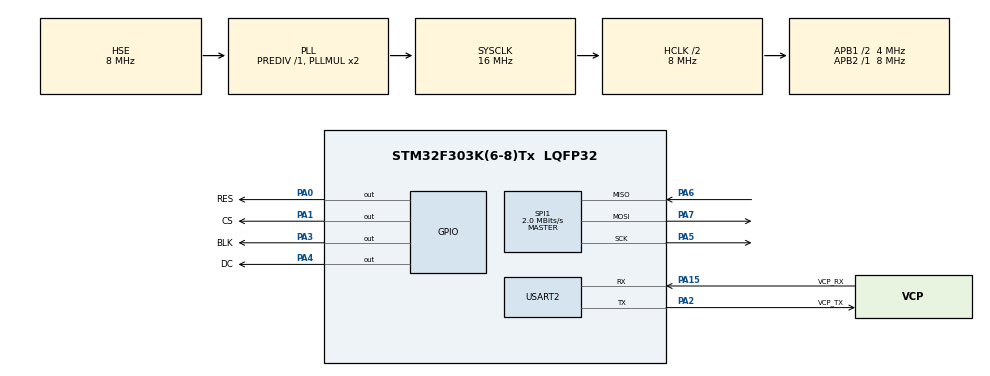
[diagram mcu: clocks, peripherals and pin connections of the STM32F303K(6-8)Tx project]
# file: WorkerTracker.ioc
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Mcu.Family=STM32F3
Mcu.Name=STM32F303K(6-8)Tx
Mcu.Package=LQFP32
NVIC.PriorityGroup=NVIC_PRIORITYGROUP_4
PA0.GPIO_Label=RES
PA0.GPIO_PuPd=GPIO_PULLDOWN
PA0.Signal=GPIO_Output
PA1.GPIO_Label=CS
PA1.GPIO_PuPd=GPIO_PULLDOWN
PA1.PinState=GPIO_PIN_RESET
PA1.Signal=GPIO_Output
PA13.GPIO_Label=SWDIO
PA13.Mode=Serial_Wire
PA13.Signal=SYS_JTMS-SWDIO
PA14.GPIO_Label=SWCLK
PA14.Mode=Serial_Wire
PA14.Signal=SYS_JTCK-SWCLK
PA15.GPIO_Label=VCP_RX
PA15.Mode=Asynchronous
PA15.Signal=USART2_RX
PA2.GPIO_Label=VCP_TX
PA2.Mode=Asynchronous
PA2.Signal=USART2_TX
PA3.GPIO_Label=BLK
PA3.GPIO_PuPd=GPIO_PULLDOWN
PA3.Signal=GPIO_Output
PA4.GPIO_Label=DC
PA4.GPIO_PuPd=GPIO_PULLDOWN
PA4.Signal=GPIO_Output
PA5.Mode=Full_Duplex_Master
PA5.Signal=SPI1_SCK
PA6.Mode=Full_Duplex_Master
PA6.Signal=SPI1_MISO
PA7.Mode=Full_Duplex_Master
PA7.Signal=SPI1_MOSI
PF0\ /\ OSC_IN.GPIO_Label=MCO
PF0\ /\ OSC_IN.Mode=HSE-External-Clock-Source
PF0\ /\ OSC_IN.Signal=RCC_OSC_IN
ProjectManager.HeapSize=0x200
ProjectManager.StackSize=0x400
ProjectManager.TargetToolchain=STM32CubeIDE
RCC.AHBCLKDivider=RCC_SYSCLK_DIV2
RCC.AHBFreq_Value=8000000
RCC.APB1CLKDivider=RCC_HCLK_DIV2
RCC.APB1Freq_Value=4000000
RCC.APB1TimFreq_Value=8000000
RCC.APB2Freq_Value=8000000
RCC.APB2TimFreq_Value=8000000
RCC.CortexFreq_Value=8000000
RCC.HCLKFreq_Value=8000000
RCC.HSE_VALUE=8000000
RCC.HSI_VALUE=8000000
RCC.PLLSourceVirtual=RCC_PLLSOURCE_HSE
RCC.SYSCLKFreq_VALUE=16000000
RCC.SYSCLKSourceVirtual=RCC_SYSCLKSOURCE_PLLCLK
SPI1.BaudRatePrescaler=SPI_BAUDRATEPRESCALER_4
SPI1.CalculateBaudRate=2.0 MBits/s
SPI1.DataSize=SPI_DATASIZE_8BIT
SPI1.Direction=SPI_DIRECTION_2LINES
SPI1.Mode=SPI_MODE_MASTER
SPI1.VirtualType=VM_MASTER
USART2.VirtualMode-Asynchronous=VM_ASYNC
board=NUCLEO-F303K8

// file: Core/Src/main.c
/* USER CODE BEGIN Header */
/**
  ******************************************************************************
  * @file           : main.c
  * @brief          : Main program body
  ******************************************************************************
  * @attention
  *
  * Copyright (c) 2023 STMicroelectronics.
  * All rights reserved.
  *
  * This software is licensed under terms that can be found in the LICENSE file
  * in the root directory of this software component.
  * If no LICENSE file comes with this software, it is provided AS-IS.
  *
  ******************************************************************************
  */
/* USER CODE END Header */
#include "main.h"
#include "spi.h"
#include "usart.h"
#include "gpio.h"

/* USER CODE BEGIN Includes */
#include "st7789.h"
/* USER CODE END Includes */

void SystemClock_Config(void);

int main(void)
{

  /* MCU Configuration--------------------------------------------------------*/

  /* Reset of all peripherals, Initializes the Flash interface and the Systick. */
  HAL_Init();

  /* Configure the system clock */
  SystemClock_Config();

  /* Initialize all configured peripherals */
  MX_GPIO_Init();
  MX_USART2_UART_Init();
  MX_SPI1_Init();
  /* USER CODE BEGIN 2 */
//  SPI1->CR1 |= (1<<6);
  /* USER CODE END 2 */

  /* Infinite loop */
  /* USER CODE BEGIN WHILE */

  ST7789_Init(128, 128);
  	  // Инициализация входа для кнопки
      // Тест вывода основных цветов
//      ST7789_FillScreen(BLACK);
//      ST7789_SetBL(0);
  HAL_GPIO_WritePin(GPIOA, GPIO_PIN_3, 0);
  while (1)
  {
//	  ST7789_Init(128, 128);
////	  	  // Инициализация входа для кнопки
////	      // Тест вывода основных цветов
//	      ST7789_FillScreen(BLACK);
//	      ST7789_SetBL(100);
//
//
//	      uint16_t color = RGB565(255, 0, 0);
//	      ST7789_FillScreen(color);
//	      HAL_Delay(500);
//
//	      color = RGB565(0, 255, 0);
//	      ST7789_FillScreen(color);
//	      HAL_Delay(500);
//
//	      color = RGB565(50, 55, 50);
//	      ST7789_FillScreen(color);
//	      HAL_Delay(500);
//
//	      color = RGB565(0, 0, 255);
//	      ST7789_FillScreen(color);
//	      HAL_Delay(500);
//
//	      color = RGB565(255, 255, 0);
//	      ST7789_FillScreen(color);
//	      HAL_Delay(500);
//
//	      color = RGB565(255, 0, 255);
//	      ST7789_FillScreen(color);
//	      HAL_Delay(500);
//
//	      color = RGB565(0, 255, 255);
//	      ST7789_FillScreen(color);
//	      HAL_Delay(500);
//
//	      color = RGB565(255, 255, 255);
//	      ST7789_FillScreen(color);
//	      HAL_Delay(500);
    /* USER CODE END WHILE */

  }
}

void SystemClock_Config(void)
{
  RCC_OscInitTypeDef RCC_OscInitStruct = {0};
  RCC_ClkInitTypeDef RCC_ClkInitStruct = {0};

  /** Initializes the RCC Oscillators according to the specified parameters
  * in the RCC_OscInitTypeDef structure.
  */
  RCC_OscInitStruct.OscillatorType = RCC_OSCILLATORTYPE_HSE;
  RCC_OscInitStruct.HSEState = RCC_HSE_BYPASS;
  RCC_OscInitStruct.HSEPredivValue = RCC_HSE_PREDIV_DIV1;
  RCC_OscInitStruct.HSIState = RCC_HSI_ON;
  RCC_OscInitStruct.PLL.PLLState = RCC_PLL_ON;
  RCC_OscInitStruct.PLL.PLLSource = RCC_PLLSOURCE_HSE;
  RCC_OscInitStruct.PLL.PLLMUL = RCC_PLL_MUL2;
  if (HAL_RCC_OscConfig(&RCC_OscInitStruct) != HAL_OK)
  {
    Error_Handler();
  }

  /** Initializes the CPU, AHB and APB buses clocks
  */
  RCC_ClkInitStruct.ClockType = RCC_CLOCKTYPE_HCLK|RCC_CLOCKTYPE_SYSCLK
                              |RCC_CLOCKTYPE_PCLK1|RCC_CLOCKTYPE_PCLK2;
  RCC_ClkInitStruct.SYSCLKSource = RCC_SYSCLKSOURCE_PLLCLK;
  RCC_ClkInitStruct.AHBCLKDivider = RCC_SYSCLK_DIV2;
  RCC_ClkInitStruct.APB1CLKDivider = RCC_HCLK_DIV2;
  RCC_ClkInitStruct.APB2CLKDivider = RCC_HCLK_DIV1;

  if (HAL_RCC_ClockConfig(&RCC_ClkInitStruct, FLASH_LATENCY_0) != HAL_OK)
  {
    Error_Handler();
  }
}

void Error_Handler(void)
{
  __disable_irq();
  while (1)
  {
  }
}
